# ESP32-S2 register map
Vendor: ESPRESSIF SYSTEMS (SHANGHAI) CO., LTD.; Series: ESP32 S-Series; File version: 20
CPU: Xtensa LX7 r0p0, little endian, no MPU, no FPU, 0 interrupt priority bits
Address unit: 32 bits
Registers are 32-bit, read-write, reset 0x0 unless marked. A register's access mark holds for its fields unless they carry their own. Offsets are from the block's base; [hi:lo] are bit positions; {n}, {i} and the like mark numbered series.

## GPIO_SD — Sigma-Delta Modulation
Base 0x3F404F00
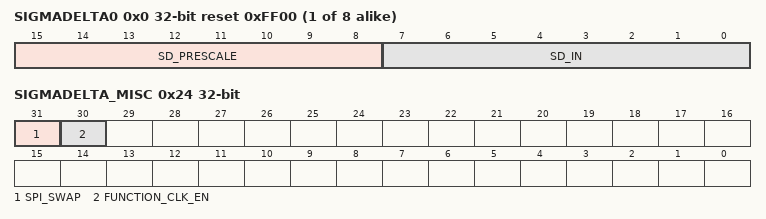
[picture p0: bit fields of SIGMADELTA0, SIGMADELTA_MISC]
{0x0+4i} SIGMADELTA{i} (i=0..7) reset 0xFF00 — Duty-cycle configuration register of SDM{i}
  [15:8] SD_PRESCALE — This field is used to set a divider value to divide APB clock.
  [7:0] SD_IN — This field is used to configure the duty cycle of sigma delta modulation output.
0x20 SIGMADELTA_CG — Clock gating configuration register
  [31] CLK_EN — Clock enable bit of configuration registers for sigma delta modulation.
0x24 SIGMADELTA_MISC — MISC register
  [31] SPI_SWAP — Reserved.
  [30] FUNCTION_CLK_EN — Clock enable bit of sigma delta modulation.
0x28 SIGMADELTA_VERSION reset 0x1802260 — Version control register
  [27:0] GPIO_SD_DATE — Version control register.

## HMAC — HMAC (Hash-based Message Authentication Code) Accelerator
Base 0x6003E000
0x40 SET_START wo — HMAC start control register
  [0] SET_START — Set this bit to enable HMAC.
0x44 SET_PARA_PURPOSE wo — HMAC parameter configuration register
  [3:0] PURPOSE_SET — Set hmac purpose.
0x48 SET_PARA_KEY wo — HMAC key configuration register
  [2:0] KEY_SET — Select hmac key.
0x4C SET_PARA_FINISH wo — HMAC configuration completion register
  [0] SET_PARA_END — Set this bit to finish HMAC configuration.
0x50 SET_MESSAGE_ONE wo — HMAC one message control register
  [0] SET_TEXT_ONE — Call SHA to calculate one message block.
0x54 SET_MESSAGE_ING wo — HMAC message continue register
  [0] SET_TEXT_ING — Set this bit to show there are still some message blocks to be processed.
0x58 SET_MESSAGE_END wo — HMAC message end register
  [0] SET_TEXT_END — Set this bit to start hardware padding.
0x5C SET_RESULT_FINISH wo — HMAC read result completion register
  [0] SET_RESULT_END — Set this bit to end upstream and clear the calculation result.
0x60 SET_INVALIDATE_JTAG wo — Invalidate JTAG result register
  [0] SET_INVALIDATE_JTAG — Set this bit to clear calculation results in JTAG re-enable function under downstream mode.
0x64 SET_INVALIDATE_DS wo — Invalidate digital signature result register
  [0] SET_INVALIDATE_DS — Set this bit to clear calculation results in DS function under downstream mode.
0x68 QUERY_ERROR ro — The matching result between key and purpose user configured
  [0] QUREY_CHECK — Hmac error status. 0: hmac key and purpose match. 1: error.
0x6C QUERY_BUSY ro — The busy state of HMAC module
  [0] BUSY_STATE — The state of Hmac. 1'b0: idle. 1'b1: busy.
{0x80+4i} WR_MESSAGE_{i} (i=0..15) wo — Message register {i}
  [31:0] WDATA — Store the %sth 32-bit of message.
{0xC0+4i} RD_RESULT_{i} (i=0..7) ro — Hash result register {i}
  [31:0] RDATA — Read the %sth 32-bit of hash result.
0xF0 SET_MESSAGE_PAD wo — Software padding register
  [0] SET_TEXT_PAD — Set this bit to let software do padding job.
0xF4 ONE_BLOCK wo — One block message register.
  [0] SET_ONE_BLOCK — Set this bit to show no padding is required.
0xF8 DATE reset 0x20190402 — Version control register
  [29:0] DATE — Version control register.

## RNG — Hardware Random Number Generator
Base 0x60035000
0x110 DATA access not given — Random number data

## RSA — RSA (Rivest Shamir Adleman) Accelerator
Base 0x6003C000
0x800 M_PRIME — Register to store M'
  [31:0] M_PRIME — Stores M'.
0x804 MODE — RSA length mode
  [6:0] MODE — Stores the mode of modular exponentiation.
0x808 CLEAN ro — RSA clean register
  [0] CLEAN — The content of this bit is 1 when memories complete initialization.
0x80C MODEXP_START wo — Modular exponentiation starting bit
  [0] MODEXP_START — Set this bit to 1 to start the modular exponentiation.
0x810 MODMULT_START wo — Modular multiplication starting bit
  [0] MODMULT_START — Set this bit to 1 to start the modular multiplication.
0x814 MULT_START wo — Normal multiplication starting bit
  [0] MULT_START — Set this bit to 1 to start the multiplication.
0x818 IDLE ro — RSA idle register
  [0] IDLE — The content of this bit is 1 when the RSA accelerator is idle.
0x81C CLEAR_INTERRUPT wo — RSA clear interrupt register
  [0] CLEAR_INTERRUPT — Set this bit to 1 to clear the RSA interrupts.
0x820 CONSTANT_TIME reset 0x1 — The constant_time option
  [0] CONSTANT_TIME — Set this bit to 0 to enable the acceleration option of constant_time for modular exponentiation. Set to 1 to disable the acceleration (by default).
0x824 SEARCH_ENABLE — The search option
  [0] SEARCH_ENABLE — Set this bit to 1 to enable the acceleration option of search for modular exponentiation. Set to 0 to disable the acceleration (by default).
0x828 SEARCH_POS — The search position
  [11:0] SEARCH_POS — Is used to configure the starting address when the acceleration option of search is used.
0x82C INTERRUPT_ENA reset 0x1 — RSA interrupt enable register
  [0] INTERRUPT_ENA — Set this bit to 1 to enable the RSA interrupt. This option is enabled by default.
0x830 DATE reset 0x20190425 — Version control register
  [29:0] DATE — Version control register.
